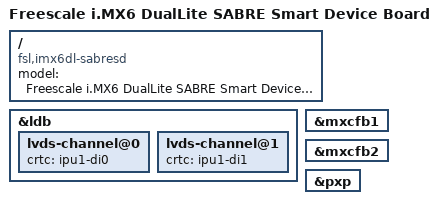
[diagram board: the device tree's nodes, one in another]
// SPDX-License-Identifier: (GPL-2.0+ OR MIT)
/*
 * Copyright (C) 2018 BTicino
 * Copyright (C) 2018 Amarula Solutions B.V.
 */

/dts-v1/;

#include "imx6dl.dtsi"
#include "imx6qdl-mx6dsysd.dtsi"

/ {
	model = "Freescale i.MX6 DualLite SABRE Smart Device Board";
	compatible = "fsl,imx6dl-sabresd", "fsl,imx6dl";
};

&ldb {
	lvds-channel@0 {
		crtc = "ipu1-di0";
	};

	lvds-channel@1 {
		crtc = "ipu1-di1";
	};
};

&mxcfb1 {
	status = "okay";
};

&mxcfb2 {
	status = "okay";
};

&pxp {
	status = "okay";
};
